# ATmega328PB register map
Vendor: Atmel; File version: 1.0
CPU: other r0p0, little endian, no MPU, no FPU, 4 interrupt priority bits
Registers are 8-bit, read-write, reset 0x0 unless marked. A register's access mark holds for its fields unless they carry their own. Offsets are from the block's base; [hi:lo] are bit positions.

## TWI1
Base 0x000000D8
0x00 TWBR1 — TWI Bit Rate register
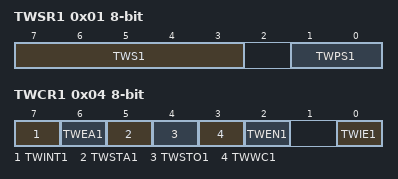
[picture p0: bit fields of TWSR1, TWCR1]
0x01 TWSR1 — TWI Status Register
  [7:3] TWS1 — TWI Status
  [1:0] TWPS1 — TWI Prescaler
    0=1; 1=4; 2=16; 3=64
0x02 TWAR1 — TWI (Slave) Address register
0x03 TWDR1 — TWI Data register
0x04 TWCR1 — TWI Control Register
  [7] TWINT1 — TWI Interrupt Flag
  [6] TWEA1 — TWI Enable Acknowledge Bit
  [5] TWSTA1 — TWI Start Condition Bit
  [4] TWSTO1 — TWI Stop Condition Bit
  [3] TWWC1 — TWI Write Collition Flag
  [2] TWEN1 — TWI Enable Bit
  [0] TWIE1 — TWI Interrupt Enable
0x05 TWAMR1 — TWI (Slave) Address Mask Register
  [7:1] TWAM1

## USART0
Base 0x000000C0
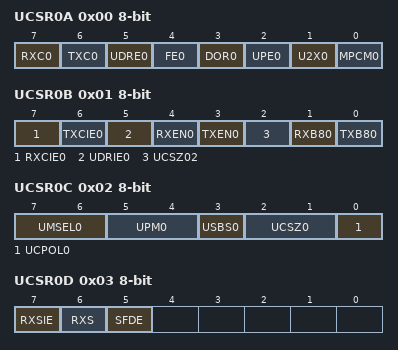
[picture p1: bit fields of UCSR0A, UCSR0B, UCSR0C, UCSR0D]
0x00 UCSR0A — USART Control and Status Register A
  [7] RXC0 — USART Receive Complete
  [6] TXC0 — USART Transmitt Complete
  [5] UDRE0 — USART Data Register Empty
  [4] FE0 — Framing Error
  [3] DOR0 — Data overRun
  [2] UPE0 — Parity Error
  [1] U2X0 — Double the USART transmission speed
  [0] MPCM0 — Multi-processor Communication Mode
0x01 UCSR0B — USART Control and Status Register B
  [7] RXCIE0 — RX Complete Interrupt Enable
  [6] TXCIE0 — TX Complete Interrupt Enable
  [5] UDRIE0 — USART Data register Empty Interrupt Enable
  [4] RXEN0 — Receiver Enable
  [3] TXEN0 — Transmitter Enable
  [2] UCSZ02 — Character Size
  [1] RXB80 — Receive Data Bit 8
  [0] TXB80 — Transmit Data Bit 8
0x02 UCSR0C — USART Control and Status Register C
  [7:6] UMSEL0 — USART Mode Select
    0=Asynchronous USART; 1=Synchronous USART; 3=Master SPI
  [5:4] UPM0 — Parity Mode Bits
    0=Disabled; 2=Enabled, Even Parity; 3=Enabled, Odd Parity
  [3] USBS0 — Stop Bit Select
    0=1-bit; 1=2-bit
  [2:1] UCSZ0 — Character Size
  [0] UCPOL0 — Clock Polarity
0x03 UCSR0D — USART Control and Status Register D
  [7] RXSIE — USART RX Start Interrupt Enable
  [6] RXS — USART RX Start
  [5] SFDE — Start frame detection enable
0x04 UBRR0 16-bit (reset mask 0xFF) — USART Baud Rate Register Bytes
0x06 UDR0 — USART I/O Data Register 0

## USART1
Base 0x000000C8
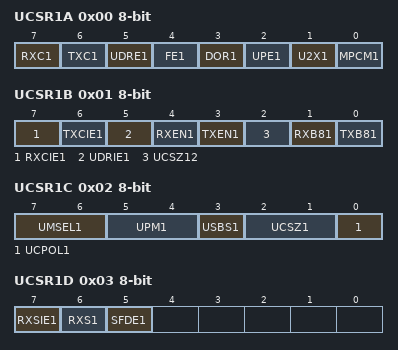
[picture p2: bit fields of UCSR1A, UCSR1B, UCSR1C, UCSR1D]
0x00 UCSR1A — USART Control and Status Register A
  [7] RXC1 — USART Receive Complete
  [6] TXC1 — USART Transmitt Complete
  [5] UDRE1 — USART Data Register Empty
  [4] FE1 — Framing Error
  [3] DOR1 — Data overRun
  [2] UPE1 — Parity Error
  [1] U2X1 — Double the USART transmission speed
  [0] MPCM1 — Multi-processor Communication Mode
0x01 UCSR1B — USART Control and Status Register B
  [7] RXCIE1 — RX Complete Interrupt Enable
  [6] TXCIE1 — TX Complete Interrupt Enable
  [5] UDRIE1 — USART Data register Empty Interrupt Enable
  [4] RXEN1 — Receiver Enable
  [3] TXEN1 — Transmitter Enable
  [2] UCSZ12 — Character Size
  [1] RXB81 — Receive Data Bit 8
  [0] TXB81 — Transmit Data Bit 8
0x02 UCSR1C — USART Control and Status Register C
  [7:6] UMSEL1 — USART Mode Select
    0=Asynchronous USART; 1=Synchronous USART; 3=Master SPI
  [5:4] UPM1 — Parity Mode Bits
    0=Disabled; 2=Enabled, Even Parity; 3=Enabled, Odd Parity
  [3] USBS1 — Stop Bit Select
    0=1-bit; 1=2-bit
  [2:1] UCSZ1 — Character Size
  [0] UCPOL1 — Clock Polarity
0x03 UCSR1D — USART Control and Status Register D
  [7] RXSIE1 — USART RX Start Interrupt Enable
  [6] RXS1 — USART RX Start
  [5] SFDE1 — Start frame detection enable
0x04 UBRR1 16-bit (reset mask 0xFF) — USART Baud Rate Register Bytes
0x06 UDR1 — USART I/O Data Register

## WDT
Base 0x00000060
0x00 WDTCSR — Watchdog Timer Control Register
  [7] WDIF — Watchdog Timeout Interrupt Flag
  [6] WDIE — Watchdog Timeout Interrupt Enable
  [4] WDCE — Watchdog Change Enable
  [3] WDE — Watch Dog Enable
  [5:0] WDP — Watchdog Timer Prescaler Bits
    0=Oscillator Cycles 2K; 1=Oscillator Cycles 4K; 2=Oscillator Cycles 8K; 3=Oscillator Cycles 16K; 4=Oscillator Cycles 32K; 5=Oscillator Cycles 64K; 6=Oscillator Cycles 128K; 7=Oscillator Cycles 256K
